# K1921VG5T register map
Vendor: NIIET; Series: K1921VKx; File version: 1.1
CPU: CM4 r0p1, Endian.LITTLE endian, MPU, FPU
Registers are 32-bit, read-write, reset 0x0 unless marked. A register's access mark holds for its fields unless they carry their own. Offsets are from the block's base; [hi:lo] are bit positions; lines under a group give offsets from that group; {n}, {i} and the like mark numbered series; 'fields as' and 'values as' point back to an identical list.

## CAP0 — Capture unit control registers
Base 0x50009000
Same registers: CAP1 0x5000A000, CAP2 0x5000B000
0x00 TSCTR — Counter register
  [31:0] VAL — Counter value
0x04 CTRPHS — Counter Phase Sync register
  [31:0] VAL
{0x8+4i} CAPREG{i} (i=0..3) — Capture register {i}
  [31:0] VAL — Capture {i} value
0x08 PRD (alternate view of CAPREG0) — Period register
  [31:0] VAL — Period value in APWM mode
0x0C CMP (alternate view of CAPREG1) — Compare register
  [31:0] VAL — Compare value in APWM mode
0x10 PRDSHDW (alternate view of CAPREG2) — Period shadow register
  [31:0] VAL — Period shadow value in APWM mode
0x14 CMPSHDW (alternate view of CAPREG3) — Compare shadow register
  [31:0] VAL — Compare shadow value in APWM mode
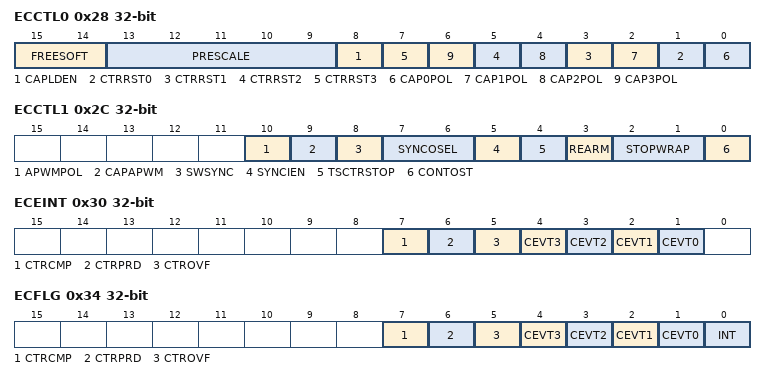
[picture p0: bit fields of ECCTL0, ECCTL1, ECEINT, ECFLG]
0x28 ECCTL0 — Capture control register 0
  [15:14] FREESOFT — Emulation mode control
    0=stop timer immedeatelly; 1=StopAtZero (stop timer when reach zero); 2=Free (normal work)
  [13:9] PRESCALE — Prescaler value
  [8] CAPLDEN — enable capture
  [2n+1] CTRRST{n} (n=0..3) — Reset counter after event {n}
  [2n] CAP{n}POL (n=0..3) — Polarity select for capture {n}
0x2C ECCTL1 — Capture control register 1
  [10] APWMPOL — High/low level APWM
  [9] CAPAPWM — Capture mode or APWM mode
  [8] SWSYNC — Software timers sync
  [7:6] SYNCOSEL — SYNCO source selection
    0=Bypass (sync in connected with sync out); 1=CTREqPrd (sync out generated when CTR = PRD); 2=Disable (sync out generate disabled)
  [5] SYNCIEN — Sync in enable
  [4] TSCTRSTOP — Enable Timer
  [3] REARM — Reset and enable controller, capture reg load
  [2:1] STOPWRAP — Stop compare value
  [0] CONTOST — Capture mode
0x30 ECEINT — Interrupt mask register
  [7] CTRCMP — enable int CTR=CMP
  [6] CTRPRD — enable int CTR=PRD
  [5] CTROVF — enable int CTR_OVF
  [n+1] CEVT{n} (n=0..3) — enable int CEVT{n}
0x34 ECFLG ro — Interrupt status register
  [7] CTRCMP — Hap interrupt CTR=CMP
  [6] CTRPRD — Hap interrupt CTR=PRD
  [5] CTROVF — Hap interrupt CTROVF
  [n+1] CEVT{n} (n=0..3) — Hap interrupt CEVT{n}
  [0] INT — indicate global interrupt
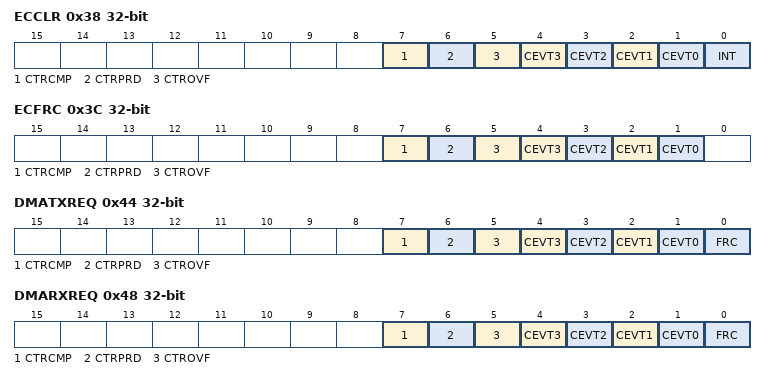
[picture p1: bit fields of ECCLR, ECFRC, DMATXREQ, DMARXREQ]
0x38 ECCLR wo — Clear interrupt register
  [7] CTRCMP — reset intstatus
  [6] CTRPRD — reset intstatus
  [5] CTROVF — reset intstatus
  [n+1] CEVT{n} (n=0..3) — reset intstatus
  [0] INT — reset global interrupt
0x3C ECFRC wo — Force interrupt register
  [7] CTRCMP — gen test interrupt
  [6] CTRPRD — gen test interrupt
  [5] CTROVF — gen test interrupt
  [n+1] CEVT{n} (n=0..3) — gen test interrupt
0x40 PEINT — Active interrupt status register
  [0] PEINT — active interrupt flag
0x44 DMATXREQ — DMA TX request mask register
  [7] CTRCMP — Send DMA request when CTR=CMP
  [6] CTRPRD — Send DMA request when CTR=PRD
  [5] CTROVF — Send DMA request when CTROVF
  [n+1] CEVT{n} (n=0..3) — Send DMA request when CEVT{n}
  [0] FRC wo — Send DMA software request
0x48 DMARXREQ — DMA RX request mask register
  fields as DMATXREQ

## SPI0 — SPI control registers
Base 0x5000F000
Same registers: SPI1 0x50010000
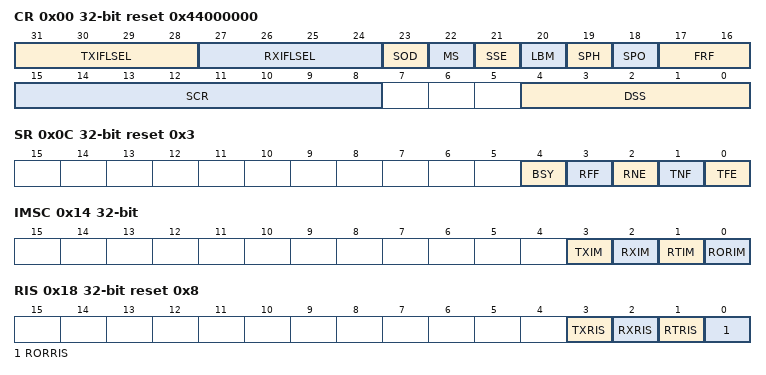
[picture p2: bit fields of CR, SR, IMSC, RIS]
0x00 CR reset 0x44000000 — Control register
  [31:28] TXIFLSEL — Transmit interrupt FIFO level select
  [27:24] RXIFLSEL — Receive interrupt FIFO level select
  [23] SOD — Disable bit data
  [22] MS — Select mode
  [21] SSE — Enable transceiver
  [20] LBM — Test loopback mode
  [19] SPH — Phase SSPCLKOUT
  [18] SPO — Polarity SSPCLKOUT
  [17:16] FRF — Select protocol
    0=SPI (SPI of Motorola); 1=SSI (SSI of Texas Instruments); 2=Microwire of National Semiconductor
  [15:8] SCR — Value divider
  [4:0] DSS — Size of data is (value + 1) bits
    {v}={v+1}bit (data size {v+1} bits) (v=3..31)
0x08 DR — Data register
  [31:0] DATA
0x0C SR ro reset 0x3 — State register
  [4] BSY — Activity flag
  [3] RFF — Indicate full receive buffer
  [2] RNE — Indicate not empty receive buffer
  [1] TNF — Indicator the transmitter FIFO buffer is not full
  [0] TFE — FIFO buffer empty flag transmitter
0x10 CPSR — Clock division factor register
  [7:0] CPSDVSR — Clock division factor. Bit0 always 0
0x14 IMSC — Mask interrupt register
  [3] TXIM — SSPTXINTR interrupt mask bit to fill 50% or less of the FIFO buffer of the transmitter
  [2] RXIM — SSPRXINTR interrupt mask bit to fill 50% or less of the receiver FIFO buffer
  [1] RTIM — Interrupt mask bit SSPRTINTR timeout receiver
  [0] RORIM — Interrupt mask bit SSPRORINTR buffer overflow receiver
0x18 RIS ro reset 0x8 — Status register interrupt without mask
  [3] TXRIS — Interrupt status before masking SSPTXINTR
  [2] RXRIS — Interrupt status before masking SSPRXINTR
  [1] RTRIS — Interrupt status before masking SSPRTINTR
  [0] RORRIS — Interrupt status before masking SSPRORINTR
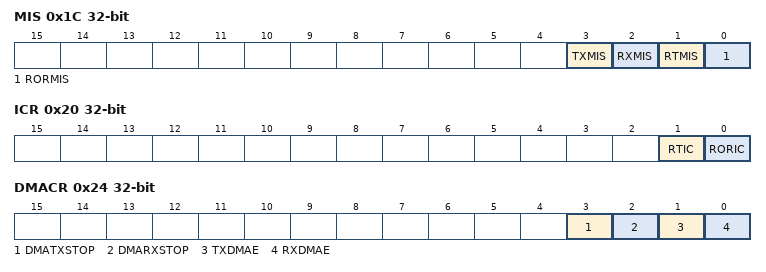
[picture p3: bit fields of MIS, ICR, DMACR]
0x1C MIS ro — Status register interrupt masking account
  [3] TXMIS — Masked interrupt status SSPTXINTR
  [2] RXMIS — Masked interrupt status SSPRXINTR
  [1] RTMIS — Masked interrupt status SSPRTINTR
  [0] RORMIS — Masked interrupt status SSPRORINTR
0x20 ICR wo — Register reset interrupt
  [1] RTIC — Reset interrupt SSPRTINTR
  [0] RORIC — Reset interrupt SSPRORINTR
0x24 DMACR — Control register DMA
  [3] DMATXSTOP — Automatic clear DMA TX request generation when channel ends all transactions
  [2] DMARXSTOP — Automatic clear DMA RX request generation when channel ends all transactions
  [1] TXDMAE — DMA enable bit transmission
  [0] RXDMAE — DMA enable bit at reception

## TMR0 — Timer 32-bit control registers
Base 0x50011000
Same registers: TMR1 0x50012000, TMR2 0x50013000, TMR3 0x50014000
0x00 CTRL — Timer control register
  [9] OUTEN — CAPCOM0 block output enable
  [8] CLKSEL — Clock Source Select
    0=SysClk (Select system Clk); 1=ExtClk (Select External Clk)
  [7] DMARXSTOP — Stop Timer when RX DMA channel ends all transactions
  [6] DMATXSTOP — Stop Timer when TX DMA channel ends all transactions
  [5:4] MODE — Count mode
    0=Stop (Timer is Stopped); 1=Up (Timer count Up); 2=Multiple (Timer count is multiple Up); 3=UpDown (Timer count is multiple Up - Down)
  [2] CLR wo — Timer Clear
  [1:0] FREESOFT — Emulation mode bits - select the behavior of the time-base counter during emulation events
    0=StopAtCLK (stop timer at next CLK tact); 1=StopAtOverload (stop timer when overload); 2=NoStop (endless count)
0x04 COUNT — Current value timer register
  [31:0] VAL — Current timer value
0x08 CLKDIV — Clock divider register
  [31:0] VAL
0x0C PERIOD — Timer period register
  [31:0] VAL
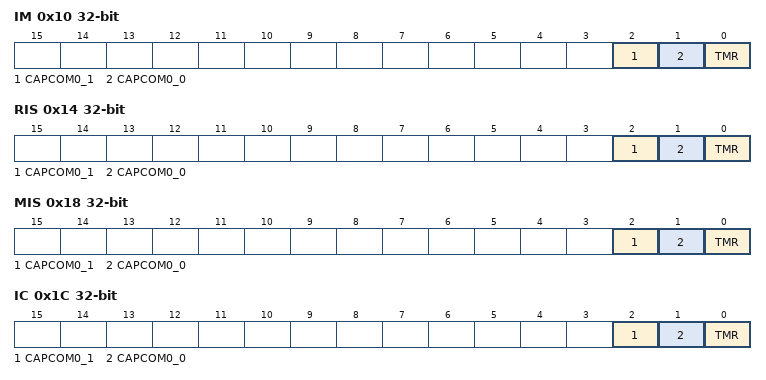
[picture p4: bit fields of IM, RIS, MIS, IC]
0x10 IM — Interrupt mask register
  [2] CAPCOM0_1 — Capcom1 Interrupt Enable
  [1] CAPCOM0_0 — Capcom0 Interrupt Enable
  [0] TMR — Timer Interrupt Enable
0x14 RIS ro — Raw Interrupt Status register
  [2] CAPCOM0_1 — Capcom1 Interrupt Status
  [1] CAPCOM0_0 — Capcom0 Interrupt Status
  [0] TMR — Timer Interrupt Status
0x18 MIS ro — Masked Interrupt Status register
  fields as RIS
0x1C IC wo — Clear Interrupt Status register
  [2] CAPCOM0_1 — Capcom1 Interrupt Clear
  [1] CAPCOM0_0 — Capcom0 Interrupt Clear
  [0] TMR — Timer Interrupt Clear
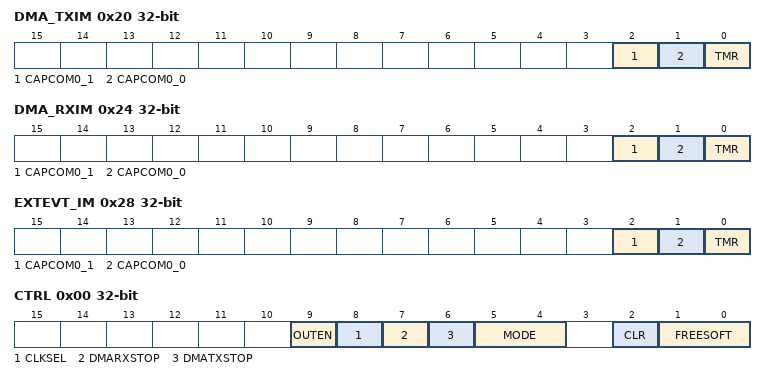
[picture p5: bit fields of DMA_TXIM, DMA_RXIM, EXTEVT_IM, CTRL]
0x20 DMA_TXIM — DMA TX request mask register
  [2] CAPCOM0_1 — Capcom1 DMA TX Request Enable
  [1] CAPCOM0_0 — Capcom0 DMA TX Request Enable
  [0] TMR — Timer DMA TX Request Enable
0x24 DMA_RXIM — DMA RX request mask register
  [2] CAPCOM0_1 — Capcom1 DMA RX Request Enable
  [1] CAPCOM0_0 — Capcom0 DMA RX Request Enable
  [0] TMR — Timer DMA RX Request Enable
0x28 EXTEVT_IM — External Event mask register
  [2] CAPCOM0_1 — Capcom1 External Event Request Enable
  [1] CAPCOM0_0 — Capcom0 External Event Request Enable
  [0] TMR — Timer External Event Request Enable
{0x100+0xC*i} CAPCOM[{i}] (i=0..1) group
  0x00 CTRL reset 0x20 — Capture / Compare Control register
    [15:14] CAPMODE — Capture Mode
    [13:12] CCISEL — Capture / Compare Input Select
    [10] SCCI ro — Synchronized Capture / Compare Input
    [8] CAP — Capture Mode
    [7:5] OUTMODE — Output Mode
    [3] CCI ro — Capture / Compare Input
    [2] OUT — Output
    [1] OVF — Capture Overflow
  0x04 VAL0 — Capture/Compare Value 0 register
    [31:0] VAL
  0x08 VAL1 — Capture/Compare Value 1 register
    [31:0] VAL
